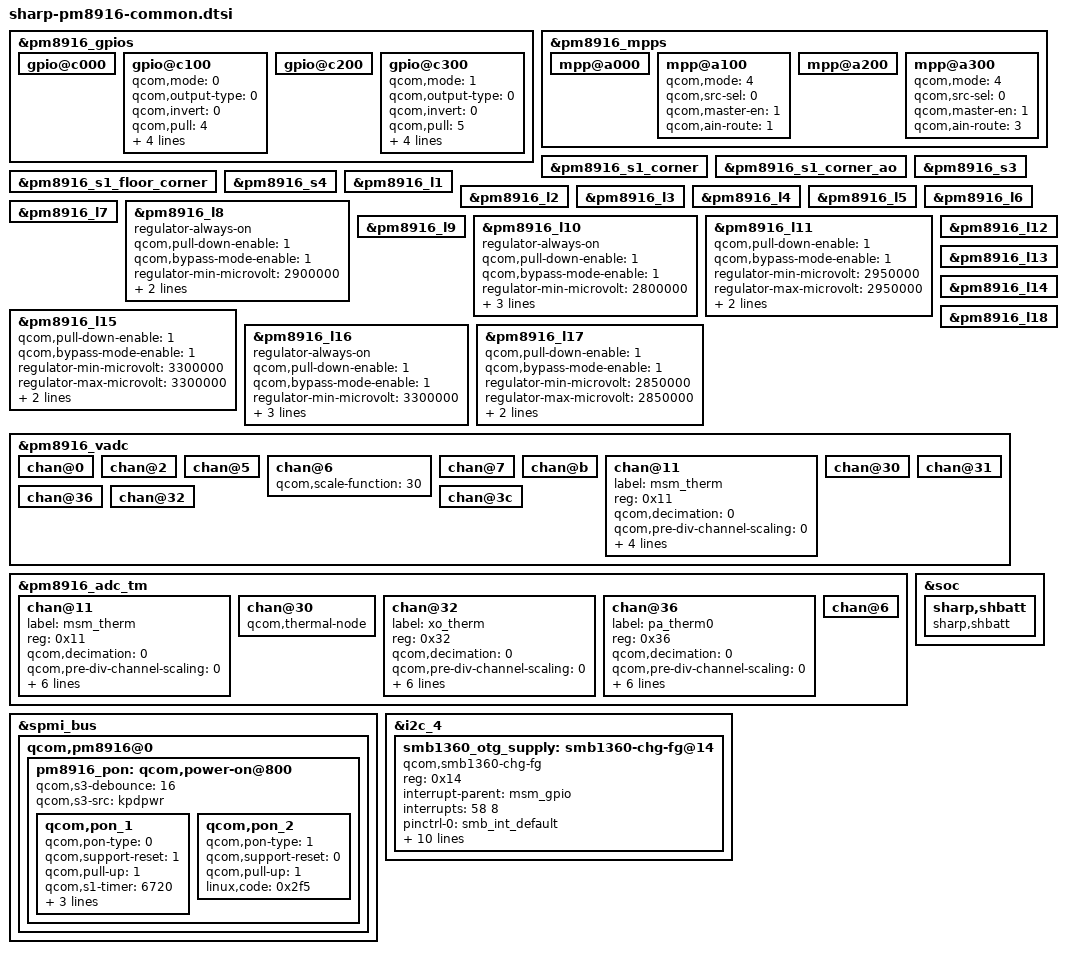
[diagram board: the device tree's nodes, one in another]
/* Copyright (c) 2014, The Linux Foundation. All rights reserved.
 *
 * This program is free software; you can redistribute it and/or modify
 * it under the terms of the GNU General Public License version 2 and
 * only version 2 as published by the Free Software Foundation.
 *
 * This program is distributed in the hope that it will be useful,
 * but WITHOUT ANY WARRANTY; without even the implied warranty of
 * MERCHANTABILITY or FITNESS FOR A PARTICULAR PURPOSE.  See the
 * GNU General Public License for more details.
 */

/*****************************************/
/*  pm8916-gpios: qpnp-pin               */
/*****************************************/

&pm8916_gpios {
	gpio@c000 { /* GPIO 1 */
		/* UIM_BATT_ALM_GPIO_1 */
		/* Qualcomm Settings */
	};

	gpio@c100 { /* GPIO 2 */
		/* Not used */
		qcom,mode = <0>;		/* DIG_IN */
		qcom,output-type = <0>;		/* CMOS */
		qcom,invert = <0>;		/* DISABLE */
		qcom,pull = <4>;		/* PULL_DN */
		qcom,vin-sel = <3>;		/* L5 */
		qcom,out-strength = <1>;	/* LOW */
		qcom,src-sel = <0>;		/* CONSTANT */
		qcom,master-en = <1>;		/* ENSABLE */
		status = "okay";
	};

	gpio@c200 { /* GPIO 3 */
		/* WCN_LDO_EN_GPIO_3 */
		/* Qualcomm Settings */
	};

	gpio@c300 { /* GPIO 4 */
		/* DTV_PWR_EN */
		qcom,mode = <1>;		/* DIG_OUT */
		qcom,output-type = <0>;		/* CMOS */
		qcom,invert = <0>;		/* DISABLE */
		qcom,pull = <5>;		/* NO_PULL */
		qcom,vin-sel = <3>;		/* L5 */
		qcom,out-strength = <1>;	/* LOW */
		qcom,src-sel = <0>;		/* CONSTANT */
		qcom,master-en = <1>;		/* ENSABLE */
		status = "okay";
	};
};

/*****************************************/
/*  pm8916-mpps: qpnp-pin                */
/*****************************************/

&pm8916_mpps {
	mpp@a000 { /* MPP 1 */
		/* VDD_PX_BIAS_MPP_1 */
		/* Qualcomm Settings */
	};

	mpp@a100 { /* MPP 2 */
		/* MSM_THRMO */
		qcom,mode = <4>;		/* AIN */
		qcom,src-sel = <0>;		/* CONSTANT */
		qcom,master-en = <1>;	/* ENSABLE */
		qcom,ain-route = <1>;	/* AMUX6 */
		status = "okay";
	};

	mpp@a200 { /* MPP 3 */
		/* VREF_DAC_MPP_3 */
		/* Qualcomm Settings */
	};

	mpp@a300 { /* MPP 4 */
		/* VCHG */
		qcom,mode = <4>;		/* AIN */
		qcom,src-sel = <0>;		/* CONSTANT */
		qcom,master-en = <1>;	/* ENSABLE */
		qcom,ain-route = <3>;	/* AMUX8 */
		status = "okay";
	};
};

/*****************************************/
/*  pm8916: rpm-regulator                */
/*****************************************/

&pm8916_s1_corner { /* regulator-s1-corner */
};

&pm8916_s1_corner_ao { /* regulator-s1-corner-ao */
};

&pm8916_s1_floor_corner { /* regulator-s1-floor-corner */
};

&pm8916_s3 { /* regulator-s3 */
};

&pm8916_s4 { /* regulator-s4 */
};

&pm8916_l1 { /* pm8916_l1 */
};

&pm8916_l2 { /* pm8916_l2 */
};

&pm8916_l3 { /* pm8916_l3 */
};

&pm8916_l4 { /* pm8916_l4 */
};

&pm8916_l5 { /* pm8916_l5 */
};

&pm8916_l6 { /* pm8916_l6 */
};

&pm8916_l7 { /* pm8916_l7 */
};

&pm8916_l8 { /* pm8916_l8 */
	regulator-always-on;
	qcom,pull-down-enable = <1>;
//	qcom,auto-mode-enable = <0>;
	qcom,bypass-mode-enable = <1>;
	regulator-min-microvolt = <2900000>;
	regulator-max-microvolt = <2900000>;
	qcom,init-voltage = <2900000>;
	status = "okay";
};

&pm8916_l9 { /* pm8916_l9 */
};

&pm8916_l10 { /* pm8916_l10 */
	regulator-always-on;
	qcom,pull-down-enable = <1>;
//	qcom,auto-mode-enable = <0>;
	qcom,bypass-mode-enable = <1>;
	regulator-min-microvolt = <2800000>;
	regulator-max-microvolt = <2800000>;
	qcom,init-voltage = <2800000>;
	qcom,init-pin-ctrl-mode = <16>;
	status = "okay";
};

&pm8916_l11 { /* pm8916_l11 */
//	regulator-always-on;
	qcom,pull-down-enable = <1>;
//	qcom,auto-mode-enable = <0>;
	qcom,bypass-mode-enable = <1>;
	regulator-min-microvolt = <2950000>;
	regulator-max-microvolt = <2950000>;
	qcom,init-voltage = <2950000>;
	qcom,init-ldo-mode = <1>;
	status = "okay";
};

&pm8916_l12 { /* pm8916_l12 */
};

&pm8916_l13 { /* pm8916_l13 */
};

&pm8916_l14 { /* pm8916_l14 */
};

&pm8916_l15 { /* pm8916_l15 */
//	regulator-always-on;
	qcom,pull-down-enable = <1>;
//	qcom,auto-mode-enable = <0>;
	qcom,bypass-mode-enable = <1>;
	regulator-min-microvolt = <3300000>;
	regulator-max-microvolt = <3300000>;
	qcom,init-voltage = <3300000>;
	qcom,init-ldo-mode = <1>;
	status = "okay";
};

&pm8916_l16 { /* pm8916_l16 */
	regulator-always-on;
	qcom,pull-down-enable = <1>;
//	qcom,auto-mode-enable = <0>;
	qcom,bypass-mode-enable = <1>;
	regulator-min-microvolt = <3300000>;
	regulator-max-microvolt = <3300000>;
	qcom,init-voltage = <3300000>;
	qcom,init-pin-ctrl-mode = <16>;
	status = "okay";
};

&pm8916_l17 { /* pm8916_l17 */
//	regulator-always-on;
	qcom,pull-down-enable = <1>;
//	qcom,auto-mode-enable = <0>;
	qcom,bypass-mode-enable = <1>;
	regulator-min-microvolt = <2850000>;
	regulator-max-microvolt = <2850000>;
	qcom,init-voltage = <2850000>;
	qcom,init-ldo-mode = <1>;
	status = "okay";
};

&pm8916_l18 { /* pm8916_l18 */
};

/*****************************************/
/*  qpnp-adc-voltage                     */
/*****************************************/

&pm8916_vadc { /* usb_in */
	chan@0 {
	};

	chan@2 { /* ireg_fb */
	};

	chan@5 { /* vcoin */
	};

	chan@6 { /* vbat_sns */
		qcom,scale-function = <30>;
	};

	chan@7 { /* vph_pwr */
	};

	chan@b { /* chg_temp */
	};

	chan@11 { /* msm_therm */
		label = "msm_therm";
		reg = <0x11>;
		qcom,decimation = <0>;
		qcom,pre-div-channel-scaling = <0>;
		qcom,calibration-type = "ratiometric";
		qcom,scale-function = <2>;
		qcom,hw-settle-time = <0>;
		qcom,fast-avg-setup = <0>;
	};

	chan@30 { /* batt_therm */
	};

	chan@31 { /* batt_id */
	};

	chan@36 { /* pa_therm0 */
	};

	chan@32 { /* xo_therm */
	};

	chan@3c { /* xo_therm_buf */
	};
};

/*****************************************/
/*  qpnp-vadc-tm                         */
/*****************************************/

&pm8916_adc_tm {
	chan@11 { /* msm_therm */
		label = "msm_therm";
		reg = <0x11>;
		qcom,decimation = <0>;
		qcom,pre-div-channel-scaling = <0>;
		qcom,calibration-type = "ratiometric";
		qcom,scale-function = <2>;
		qcom,hw-settle-time = <0>;
		qcom,fast-avg-setup = <0>;
		qcom,btm-channel-number = <0x48>;
		qcom,thermal-node;
	};

	chan@30 { /* batt_therm */
		qcom,thermal-node;
	};
	
	chan@32 {
		label = "xo_therm";
		reg = <0x32>;
		qcom,decimation = <0>;
		qcom,pre-div-channel-scaling = <0>;
		qcom,calibration-type = "ratiometric";
		qcom,scale-function = <4>;
		qcom,hw-settle-time = <2>;
		qcom,fast-avg-setup = <0>;
		qcom,btm-channel-number = <0x48>;
		qcom,thermal-node;
	};
	
	chan@36 {
		label = "pa_therm0";
		reg = <0x36>;
		qcom,decimation = <0>;
		qcom,pre-div-channel-scaling = <0>;
		qcom,calibration-type = "ratiometric";
		qcom,scale-function = <2>;
		qcom,hw-settle-time = <2>;
		qcom,fast-avg-setup = <0>;
		qcom,btm-channel-number = <0x48>;
		qcom,thermal-node;
	};

	chan@6 { /* vbat_sns */
	};
};

/*****************************************/
/*  SHARP Device Drivers                 */
/*****************************************/
&soc {
	/*---------------------------------------*/
	/*  Battery Control Driver               */
	/*---------------------------------------*/
	sharp,shbatt {
		compatible = "sharp,shbatt";
		status = "ok";
	};
};

/*****************************************/
/*  qpnp-pon  */
/*****************************************/
&spmi_bus {

	qcom,pm8916@0 {
		pm8916_pon: qcom,power-on@800 {
			qcom,s3-debounce = <16>;
			qcom,s3-src = "kpdpwr";

			qcom,pon_1 {
				qcom,pon-type = <0>;
				qcom,support-reset = <1>;
				qcom,pull-up = <1>;
				qcom,s1-timer = <6720>;
				qcom,s2-timer = <1000>;
				qcom,s2-type = <7>;
				linux,code = <116>;
			};

			qcom,pon_2 {
				qcom,pon-type = <1>;
				qcom,support-reset = <0>;
				qcom,pull-up = <1>;
				linux,code = <0x2f5>;
			};
		};
	};
};

/*****************************************/
/*  smb1360-chg-fg  Increase of stage   */
/*****************************************/
&i2c_4 {
	smb1360_otg_supply: smb1360-chg-fg@14 {
		compatible = "qcom,smb1360-chg-fg";
		reg = <0x14>;
		interrupt-parent = <&msm_gpio>;
		interrupts = <58 8>;
		pinctrl-names = "default";
		pinctrl-0 = <&smb_int_default>;
//		qcom,charging-disabled;
//		qcom,empty-soc-disabled;
		qcom,chg-inhibit-disabled;
		qcom,float-voltage-mv = <4200>;
		qcom,iterm-ma = <200>;
		qcom,recharge-thresh-mv = <100>;
		qcom,thermal-mitigation = <1500 1400 1300 1200 1100 1000 900 800 700 600 500 400 300 0>;
		qcom,fastchg-current-ma = <1050>;
		qcom,fg-voltage-min-mv = <3400>;
		qcom,fg-voltage-empty-mv = <3100>;
		regulator-name = "smb1360_otg_vreg";
	};
};
